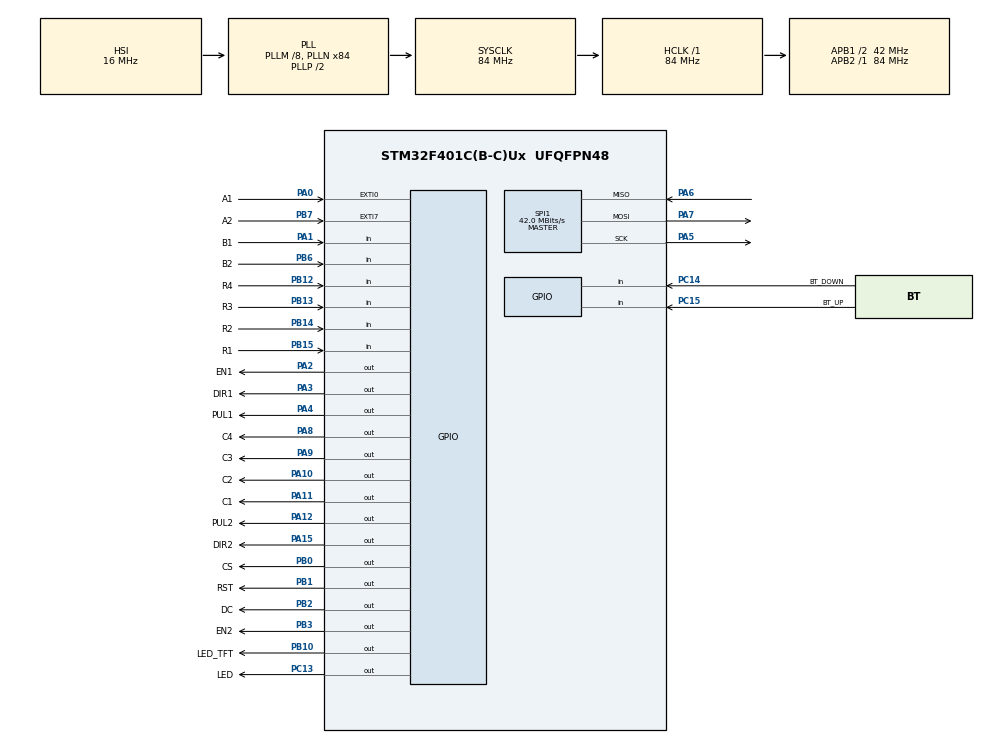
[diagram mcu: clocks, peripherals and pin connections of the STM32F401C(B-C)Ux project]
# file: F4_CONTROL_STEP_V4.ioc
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Dma.Request0=SPI1_TX
Dma.SPI1_TX.0.Direction=DMA_MEMORY_TO_PERIPH
Dma.SPI1_TX.0.FIFOMode=DMA_FIFOMODE_DISABLE
Dma.SPI1_TX.0.Instance=DMA2_Stream3
Dma.SPI1_TX.0.MemDataAlignment=DMA_MDATAALIGN_BYTE
Dma.SPI1_TX.0.MemInc=DMA_MINC_ENABLE
Dma.SPI1_TX.0.Mode=DMA_NORMAL
Dma.SPI1_TX.0.PeriphDataAlignment=DMA_PDATAALIGN_BYTE
Dma.SPI1_TX.0.PeriphInc=DMA_PINC_DISABLE
Dma.SPI1_TX.0.Priority=DMA_PRIORITY_LOW
Mcu.Family=STM32F4
Mcu.Name=STM32F401C(B-C)Ux
Mcu.Package=UFQFPN48
NVIC.DMA2_Stream3_IRQn=true\:0\:0\:false\:false\:true\:false\:true\:true
NVIC.EXTI0_IRQn=true\:0\:0\:false\:false\:true\:true\:true\:true
NVIC.EXTI9_5_IRQn=true\:0\:0\:false\:false\:true\:true\:true\:true
NVIC.PriorityGroup=NVIC_PRIORITYGROUP_4
NVIC.SPI1_IRQn=true\:0\:0\:false\:false\:true\:true\:true\:true
NVIC.TIM1_TRG_COM_TIM11_IRQn=true\:0\:0\:false\:false\:true\:true\:true\:true
NVIC.TIM1_UP_TIM10_IRQn=true\:0\:0\:false\:false\:true\:true\:true\:true
PA0-WKUP.GPIO_Label=A1
PA0-WKUP.GPIO_ModeDefaultEXTI=GPIO_MODE_IT_FALLING
PA0-WKUP.Signal=GPXTI0
PA1.GPIO_Label=B1
PA1.Signal=GPIO_Input
PA10.GPIO_Label=C2
PA10.Signal=GPIO_Output
PA11.GPIO_Label=C1
PA11.Signal=GPIO_Output
PA12.GPIO_Label=PUL2
PA12.GPIO_Speed=GPIO_SPEED_FREQ_VERY_HIGH
PA12.Signal=GPIO_Output
PA13.Mode=Serial_Wire
PA13.Signal=SYS_JTMS-SWDIO
PA14.Mode=Serial_Wire
PA14.Signal=SYS_JTCK-SWCLK
PA15.GPIO_Label=DIR2
PA15.GPIO_Speed=GPIO_SPEED_FREQ_HIGH
PA15.Signal=GPIO_Output
PA2.GPIO_Label=EN1
PA2.Signal=GPIO_Output
PA3.GPIO_Label=DIR1
PA3.GPIO_Speed=GPIO_SPEED_FREQ_HIGH
PA3.Signal=GPIO_Output
PA4.GPIO_Label=PUL1
PA4.GPIO_Speed=GPIO_SPEED_FREQ_VERY_HIGH
PA4.Signal=GPIO_Output
PA5.Mode=Full_Duplex_Master
PA5.Signal=SPI1_SCK
PA6.Mode=Full_Duplex_Master
PA6.Signal=SPI1_MISO
PA7.Mode=Full_Duplex_Master
PA7.Signal=SPI1_MOSI
PA8.GPIO_Label=C4
PA8.Signal=GPIO_Output
PA9.GPIO_Label=C3
PA9.Signal=GPIO_Output
PB0.GPIO_Label=CS
PB0.Signal=GPIO_Output
PB1.GPIO_Label=RST
PB1.Signal=GPIO_Output
PB10.GPIO_Label=LED_TFT
PB10.Signal=GPIO_Output
PB12.GPIO_Label=R4
PB12.Signal=GPIO_Input
PB13.GPIO_Label=R3
PB13.Signal=GPIO_Input
PB14.GPIO_Label=R2
PB14.Signal=GPIO_Input
PB15.GPIO_Label=R1
PB15.Signal=GPIO_Input
PB2.GPIO_Label=DC
PB2.Signal=GPIO_Output
PB3.GPIO_Label=EN2
PB3.Signal=GPIO_Output
PB6.GPIO_Label=B2
PB6.Signal=GPIO_Input
PB7.GPIO_Label=A2
PB7.GPIO_ModeDefaultEXTI=GPIO_MODE_IT_FALLING
PB7.Signal=GPXTI7
PC13-ANTI_TAMP.GPIO_Label=LED
PC13-ANTI_TAMP.Signal=GPIO_Output
PC14-OSC32_IN.GPIO_Label=BT_DOWN
PC14-OSC32_IN.Signal=GPIO_Input
PC15-OSC32_OUT.GPIO_Label=BT_UP
PC15-OSC32_OUT.Signal=GPIO_Input
PH0\ -\ OSC_IN.Mode=HSE-External-Oscillator
PH0\ -\ OSC_IN.Signal=RCC_OSC_IN
PH1\ -\ OSC_OUT.Mode=HSE-External-Oscillator
PH1\ -\ OSC_OUT.Signal=RCC_OSC_OUT
ProjectManager.HeapSize=0x200
ProjectManager.StackSize=0x400
ProjectManager.TargetToolchain=MDK-ARM V5
RCC.48MHZClocksFreq_Value=42000000
RCC.AHBFreq_Value=84000000
RCC.APB1CLKDivider=RCC_HCLK_DIV2
RCC.APB1Freq_Value=42000000
RCC.APB1TimFreq_Value=84000000
RCC.APB2Freq_Value=84000000
RCC.APB2TimFreq_Value=84000000
RCC.CortexFreq_Value=84000000
RCC.HCLKFreq_Value=84000000
RCC.HSE_VALUE=25000000
RCC.HSI_VALUE=16000000
RCC.LSE_VALUE=32768
RCC.PLLM=8
RCC.PLLN=84
RCC.SYSCLKFreq_VALUE=84000000
RCC.SYSCLKSource=RCC_SYSCLKSOURCE_PLLCLK
RCC.VCOOutputFreq_Value=168000000
SPI1.CalculateBaudRate=42.0 MBits/s
SPI1.Direction=SPI_DIRECTION_2LINES
SPI1.Mode=SPI_MODE_MASTER
SPI1.VirtualType=VM_MASTER
TIM10.Period=70-1
TIM10.Prescaler=84-1
TIM11.Period=2000-1
TIM11.Prescaler=84-1
VP_TIM10_VS_ClockSourceINT.Mode=Enable_Timer
VP_TIM11_VS_ClockSourceINT.Mode=Enable_Timer
board=custom

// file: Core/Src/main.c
/* USER CODE BEGIN Header */
/**
  ******************************************************************************
  * @file           : main.c
  * @brief          : Main program body
  ******************************************************************************
  * @attention
  *
  * Copyright (c) 2024 STMicroelectronics.
  * All rights reserved.
  *
  * This software is licensed under terms that can be found in the LICENSE file
  * in the root directory of this software component.
  * If no LICENSE file comes with this software, it is provided AS-IS.
  *
  ******************************************************************************
  */
/* USER CODE END Header */
#include "main.h"
#include "dma.h"
#include "spi.h"
#include "tim.h"
#include "gpio.h"

/* USER CODE BEGIN Includes */
#include "app.h"
#include "app_encoder.h"
/* USER CODE END Includes */

void SystemClock_Config(void);

int main(void)
{

  /* MCU Configuration--------------------------------------------------------*/

  /* Reset of all peripherals, Initializes the Flash interface and the Systick. */
  HAL_Init();

  /* Configure the system clock */
  SystemClock_Config();

  /* Initialize all configured peripherals */
  MX_GPIO_Init();
  MX_DMA_Init();
  MX_SPI1_Init();
  MX_TIM11_Init();
  MX_TIM10_Init();
  /* USER CODE BEGIN 2 */

	app_init();
  /* USER CODE END 2 */

  /* Infinite loop */
  /* USER CODE BEGIN WHILE */
  while (1)
  {
	  app_run();
    /* USER CODE END WHILE */

  }
}

void SystemClock_Config(void)
{
  RCC_OscInitTypeDef RCC_OscInitStruct = {0};
  RCC_ClkInitTypeDef RCC_ClkInitStruct = {0};

  /** Configure the main internal regulator output voltage
  */
  __HAL_RCC_PWR_CLK_ENABLE();
  __HAL_PWR_VOLTAGESCALING_CONFIG(PWR_REGULATOR_VOLTAGE_SCALE2);

  /** Initializes the RCC Oscillators according to the specified parameters
  * in the RCC_OscInitTypeDef structure.
  */
  RCC_OscInitStruct.OscillatorType = RCC_OSCILLATORTYPE_HSI;
  RCC_OscInitStruct.HSIState = RCC_HSI_ON;
  RCC_OscInitStruct.HSICalibrationValue = RCC_HSICALIBRATION_DEFAULT;
  RCC_OscInitStruct.PLL.PLLState = RCC_PLL_ON;
  RCC_OscInitStruct.PLL.PLLSource = RCC_PLLSOURCE_HSI;
  RCC_OscInitStruct.PLL.PLLM = 8;
  RCC_OscInitStruct.PLL.PLLN = 84;
  RCC_OscInitStruct.PLL.PLLP = RCC_PLLP_DIV2;
  RCC_OscInitStruct.PLL.PLLQ = 4;
  if (HAL_RCC_OscConfig(&RCC_OscInitStruct) != HAL_OK)
  {
    Error_Handler();
  }

  /** Initializes the CPU, AHB and APB buses clocks
  */
  RCC_ClkInitStruct.ClockType = RCC_CLOCKTYPE_HCLK|RCC_CLOCKTYPE_SYSCLK
                              |RCC_CLOCKTYPE_PCLK1|RCC_CLOCKTYPE_PCLK2;
  RCC_ClkInitStruct.SYSCLKSource = RCC_SYSCLKSOURCE_PLLCLK;
  RCC_ClkInitStruct.AHBCLKDivider = RCC_SYSCLK_DIV1;
  RCC_ClkInitStruct.APB1CLKDivider = RCC_HCLK_DIV2;
  RCC_ClkInitStruct.APB2CLKDivider = RCC_HCLK_DIV1;

  if (HAL_RCC_ClockConfig(&RCC_ClkInitStruct, FLASH_LATENCY_2) != HAL_OK)
  {
    Error_Handler();
  }
}

void Error_Handler(void)
{
  __disable_irq();
  while (1)
  {
  }
}
